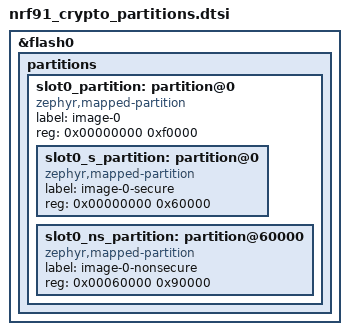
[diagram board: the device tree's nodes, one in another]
/*
 * Copyright (c) 2026 Nordic Semiconductor ASA
 *
 * SPDX-License-Identifier: LicenseRef-Nordic-5-Clause
 */

/delete-node/ &boot_partition;
/delete-node/ &slot0_partition;
/delete-node/ &slot1_partition;

&flash0 {
	/*
	 * 0x0000_0000  Primary area			(960 kB)
	 *   0x0000_0000  Primary secure image		(384 kB)
	 *   0x0006_0000  Primary non-secure image	(576 kB)
	 *
	 * Unchanged:
	 * 0x000f_0000 Protected Storage Area           ( 16 KB)
	 * 0x000f_4000 Internal Trusted Storage Area    (  8 KB)
	 * 0x000f_6000 OTP / NV counters area           (  8 KB)
	 * 0x000f_8000  Settings storage		( 32 kB)
	 */
	partitions {
		ranges;
		#address-cells = <1>;
		#size-cells = <1>;

		slot0_partition: partition@0 {
			compatible = "zephyr,mapped-partition";
			label = "image-0";
			reg = <0x00000000 0xf0000>;
			ranges = <0x0 0x00000000 0xf0000>;
			#address-cells = <1>;
			#size-cells = <1>;

			slot0_s_partition: partition@0 {
				compatible = "zephyr,mapped-partition";
				label = "image-0-secure";
				reg = <0x00000000 0x60000>;
			};

			slot0_ns_partition: partition@60000 {
				compatible = "zephyr,mapped-partition";
				label = "image-0-nonsecure";
				reg = <0x00060000 0x90000>;
			};
		};
	};
};
